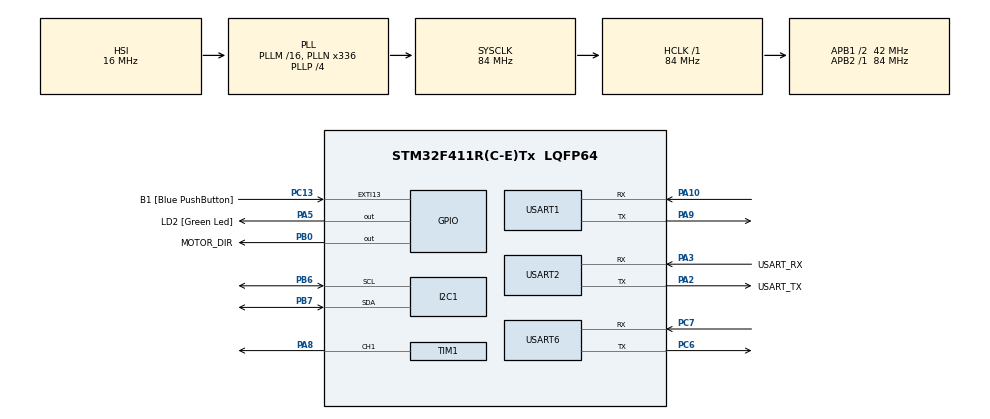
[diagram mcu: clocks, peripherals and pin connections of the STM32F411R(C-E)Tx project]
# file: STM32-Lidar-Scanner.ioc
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Dma.Request0=USART1_RX
Dma.Request1=USART6_TX
Dma.USART1_RX.0.Direction=DMA_PERIPH_TO_MEMORY
Dma.USART1_RX.0.FIFOMode=DMA_FIFOMODE_DISABLE
Dma.USART1_RX.0.Instance=DMA2_Stream2
Dma.USART1_RX.0.MemDataAlignment=DMA_MDATAALIGN_BYTE
Dma.USART1_RX.0.MemInc=DMA_MINC_ENABLE
Dma.USART1_RX.0.Mode=DMA_CIRCULAR
Dma.USART1_RX.0.PeriphDataAlignment=DMA_PDATAALIGN_BYTE
Dma.USART1_RX.0.PeriphInc=DMA_PINC_DISABLE
Dma.USART1_RX.0.Priority=DMA_PRIORITY_HIGH
Dma.USART6_TX.1.Direction=DMA_MEMORY_TO_PERIPH
Dma.USART6_TX.1.FIFOMode=DMA_FIFOMODE_DISABLE
Dma.USART6_TX.1.Instance=DMA2_Stream6
Dma.USART6_TX.1.MemDataAlignment=DMA_MDATAALIGN_BYTE
Dma.USART6_TX.1.MemInc=DMA_MINC_ENABLE
Dma.USART6_TX.1.Mode=DMA_NORMAL
Dma.USART6_TX.1.PeriphDataAlignment=DMA_PDATAALIGN_BYTE
Dma.USART6_TX.1.PeriphInc=DMA_PINC_DISABLE
Dma.USART6_TX.1.Priority=DMA_PRIORITY_LOW
FREERTOS.Tasks01=defaultTask,24,128,StartDefaultTask,Default,NULL,Dynamic,NULL,NULL
FREERTOS.configTOTAL_HEAP_SIZE=32768
FREERTOS.configUSE_NEWLIB_REENTRANT=1
I2C1.I2C_Mode=I2C_Standard
Mcu.Family=STM32F4
Mcu.Name=STM32F411R(C-E)Tx
Mcu.Package=LQFP64
NVIC.DMA2_Stream2_IRQn=true\:5\:0\:false\:false\:true\:true\:false\:true\:true
NVIC.DMA2_Stream6_IRQn=true\:5\:0\:false\:false\:true\:true\:false\:true\:true
NVIC.EXTI15_10_IRQn=true\:5\:0\:false\:false\:true\:true\:true\:true\:true
NVIC.PriorityGroup=NVIC_PRIORITYGROUP_4
NVIC.TIM1_TRG_COM_TIM11_IRQn=true\:15\:0\:false\:false\:true\:false\:false\:true\:true
NVIC.TimeBase=TIM1_TRG_COM_TIM11_IRQn
NVIC.TimeBaseIP=TIM11
NVIC.USART1_IRQn=true\:5\:0\:false\:false\:true\:true\:true\:true\:true
NVIC.USART6_IRQn=true\:5\:0\:false\:false\:true\:true\:true\:true\:true
PA10.Mode=Asynchronous
PA10.Signal=USART1_RX
PA13.GPIO_Label=TMS
PA13.Mode=Serial_Wire
PA13.Signal=SYS_JTMS-SWDIO
PA14.GPIO_Label=TCK
PA14.Mode=Serial_Wire
PA14.Signal=SYS_JTCK-SWCLK
PA2.GPIO_Label=USART_TX
PA2.Mode=Asynchronous
PA2.Signal=USART2_TX
PA3.GPIO_Label=USART_RX
PA3.Mode=Asynchronous
PA3.Signal=USART2_RX
PA5.GPIO_Label=LD2 [Green Led]
PA5.Signal=GPIO_Output
PA8.Signal=S_TIM1_CH1
PA9.Mode=Asynchronous
PA9.Signal=USART1_TX
PB0.GPIO_Label=MOTOR_DIR
PB0.Signal=GPIO_Output
PB3.GPIO_Label=SWO
PB3.Signal=SYS_JTDO-SWO
PB6.Mode=I2C
PB6.Signal=I2C1_SCL
PB7.Mode=I2C
PB7.Signal=I2C1_SDA
PC13-ANTI_TAMP.GPIO_Label=B1 [Blue PushButton]
PC13-ANTI_TAMP.GPIO_ModeDefaultEXTI=GPIO_MODE_IT_FALLING
PC13-ANTI_TAMP.Signal=GPXTI13
PC14-OSC32_IN.Mode=LSE-External-Oscillator
PC14-OSC32_IN.Signal=RCC_OSC32_IN
PC15-OSC32_OUT.Mode=LSE-External-Oscillator
PC15-OSC32_OUT.Signal=RCC_OSC32_OUT
PC6.Mode=Asynchronous
PC6.Signal=USART6_TX
PC7.Mode=Asynchronous
PC7.Signal=USART6_RX
PH0\ -\ OSC_IN.Mode=HSE-External-Clock-Source
PH0\ -\ OSC_IN.Signal=RCC_OSC_IN
PH1\ -\ OSC_OUT.Mode=HSE-External-Clock-Source
PH1\ -\ OSC_OUT.Signal=RCC_OSC_OUT
ProjectManager.HeapSize=0x200
ProjectManager.StackSize=0x400
ProjectManager.TargetToolchain=STM32CubeIDE
RCC.48MHZClocksFreq_Value=84000000
RCC.AHBFreq_Value=84000000
RCC.APB1CLKDivider=RCC_HCLK_DIV2
RCC.APB1Freq_Value=42000000
RCC.APB1TimFreq_Value=84000000
RCC.APB2Freq_Value=84000000
RCC.APB2TimFreq_Value=84000000
RCC.CortexFreq_Value=84000000
RCC.FLatency-AdvancedSettings=FLASH_LATENCY_2
RCC.HCLKFreq_Value=84000000
RCC.HSE_VALUE=8000000
RCC.HSI_VALUE=16000000
RCC.PLLN=336
RCC.PLLP=RCC_PLLP_DIV4
RCC.SYSCLKFreq_VALUE=84000000
RCC.SYSCLKSource=RCC_SYSCLKSOURCE_PLLCLK
RCC.VCOOutputFreq_Value=336000000
SH.S_TIM1_CH1.0=TIM1_CH1,PWM Generation1 CH1
TIM1.Channel-PWM\ Generation1\ CH1=TIM_CHANNEL_1
TIM1.Period=999
TIM1.Prescaler=83
TIM1.Pulse-PWM\ Generation1\ CH1=499
USART1.VirtualMode=VM_ASYNC
USART2.VirtualMode=VM_ASYNC
USART6.VirtualMode=VM_ASYNC
VP_FREERTOS_VS_CMSIS_V2.Mode=CMSIS_V2
VP_SYS_VS_tim11.Mode=TIM11
VP_TIM1_VS_ClockSourceINT.Mode=Internal
board=NUCLEO-F411RE

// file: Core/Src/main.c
/* USER CODE BEGIN Header */
/**
  ******************************************************************************
  * @file           : main.c
  * @brief          : Main program body
  ******************************************************************************
  * @attention
  *
  * Copyright (c) 2026 STMicroelectronics.
  * All rights reserved.
  *
  * This software is licensed under terms that can be found in the LICENSE file
  * in the root directory of this software component.
  * If no LICENSE file comes with this software, it is provided AS-IS.
  *
  ******************************************************************************
  */
/* USER CODE END Header */
#include "main.h"
#include "cmsis_os.h"
#include "dma.h"
#include "i2c.h"
#include "tim.h"
#include "usart.h"
#include "gpio.h"

void SystemClock_Config(void);
void MX_FREERTOS_Init(void);

int main(void)
{

  /* MCU Configuration--------------------------------------------------------*/

  /* Reset of all peripherals, Initializes the Flash interface and the Systick. */
  HAL_Init();

  /* Configure the system clock */
  SystemClock_Config();

  /* Initialize all configured peripherals */
  MX_GPIO_Init();
  MX_DMA_Init();
  MX_USART2_UART_Init();
  MX_USART1_UART_Init();
  MX_USART6_UART_Init();
  MX_TIM1_Init();
  MX_I2C1_Init();

  /* Init scheduler */
  osKernelInitialize();  /* Call init function for freertos objects (in cmsis_os2.c) */
  MX_FREERTOS_Init();

  /* Start scheduler */
  osKernelStart();

  /* We should never get here as control is now taken by the scheduler */

  /* Infinite loop */
  while (1)
  {

  }
}

void SystemClock_Config(void)
{
  RCC_OscInitTypeDef RCC_OscInitStruct = {0};
  RCC_ClkInitTypeDef RCC_ClkInitStruct = {0};

  /** Configure the main internal regulator output voltage
  */
  __HAL_RCC_PWR_CLK_ENABLE();
  __HAL_PWR_VOLTAGESCALING_CONFIG(PWR_REGULATOR_VOLTAGE_SCALE1);

  /** Initializes the RCC Oscillators according to the specified parameters
  * in the RCC_OscInitTypeDef structure.
  */
  RCC_OscInitStruct.OscillatorType = RCC_OSCILLATORTYPE_HSI;
  RCC_OscInitStruct.HSIState = RCC_HSI_ON;
  RCC_OscInitStruct.HSICalibrationValue = RCC_HSICALIBRATION_DEFAULT;
  RCC_OscInitStruct.PLL.PLLState = RCC_PLL_ON;
  RCC_OscInitStruct.PLL.PLLSource = RCC_PLLSOURCE_HSI;
  RCC_OscInitStruct.PLL.PLLM = 16;
  RCC_OscInitStruct.PLL.PLLN = 336;
  RCC_OscInitStruct.PLL.PLLP = RCC_PLLP_DIV4;
  RCC_OscInitStruct.PLL.PLLQ = 4;
  if (HAL_RCC_OscConfig(&RCC_OscInitStruct) != HAL_OK)
  {
    Error_Handler();
  }

  /** Initializes the CPU, AHB and APB buses clocks
  */
  RCC_ClkInitStruct.ClockType = RCC_CLOCKTYPE_HCLK|RCC_CLOCKTYPE_SYSCLK
                              |RCC_CLOCKTYPE_PCLK1|RCC_CLOCKTYPE_PCLK2;
  RCC_ClkInitStruct.SYSCLKSource = RCC_SYSCLKSOURCE_PLLCLK;
  RCC_ClkInitStruct.AHBCLKDivider = RCC_SYSCLK_DIV1;
  RCC_ClkInitStruct.APB1CLKDivider = RCC_HCLK_DIV2;
  RCC_ClkInitStruct.APB2CLKDivider = RCC_HCLK_DIV1;

  if (HAL_RCC_ClockConfig(&RCC_ClkInitStruct, FLASH_LATENCY_2) != HAL_OK)
  {
    Error_Handler();
  }
}

void HAL_TIM_PeriodElapsedCallback(TIM_HandleTypeDef *htim)
{
  if (htim->Instance == TIM11)
  {
    HAL_IncTick();
  }
}

void Error_Handler(void)
{
  __disable_irq();
  while (1)
  {
  }
}

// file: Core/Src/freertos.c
/* USER CODE BEGIN Header */
/**
  ******************************************************************************
  * File Name          : freertos.c
  * Description        : Code for freertos applications
  ******************************************************************************
  * @attention
  *
  * Copyright (c) 2026 STMicroelectronics.
  * All rights reserved.
  *
  * This software is licensed under terms that can be found in the LICENSE file
  * in the root directory of this software component.
  * If no LICENSE file comes with this software, it is provided AS-IS.
  *
  ******************************************************************************
  */
/* USER CODE END Header */

#include "FreeRTOS.h"
#include "task.h"
#include "main.h"
#include "cmsis_os.h"

/* USER CODE BEGIN Includes */

#include "app_main.h"

/* USER CODE END Includes */

/* Definitions for defaultTask */
osThreadId_t defaultTaskHandle;
const osThreadAttr_t defaultTask_attributes = {
  .name = "defaultTask",
  .stack_size = 128 * 4,
  .priority = (osPriority_t) osPriorityNormal,
};

void StartDefaultTask(void *argument);

void MX_FREERTOS_Init(void); /* (MISRA C 2004 rule 8.1) */

void MX_FREERTOS_Init(void) {

  /* Create the thread(s) */
  /* creation of defaultTask */
  defaultTaskHandle = osThreadNew(StartDefaultTask, NULL, &defaultTask_attributes);

}

void StartDefaultTask(void *argument)
{
  /* USER CODE BEGIN StartDefaultTask */
  /* Infinite loop */
	app_main();

	vTaskDelete(NULL);
  /* USER CODE END StartDefaultTask */
}
